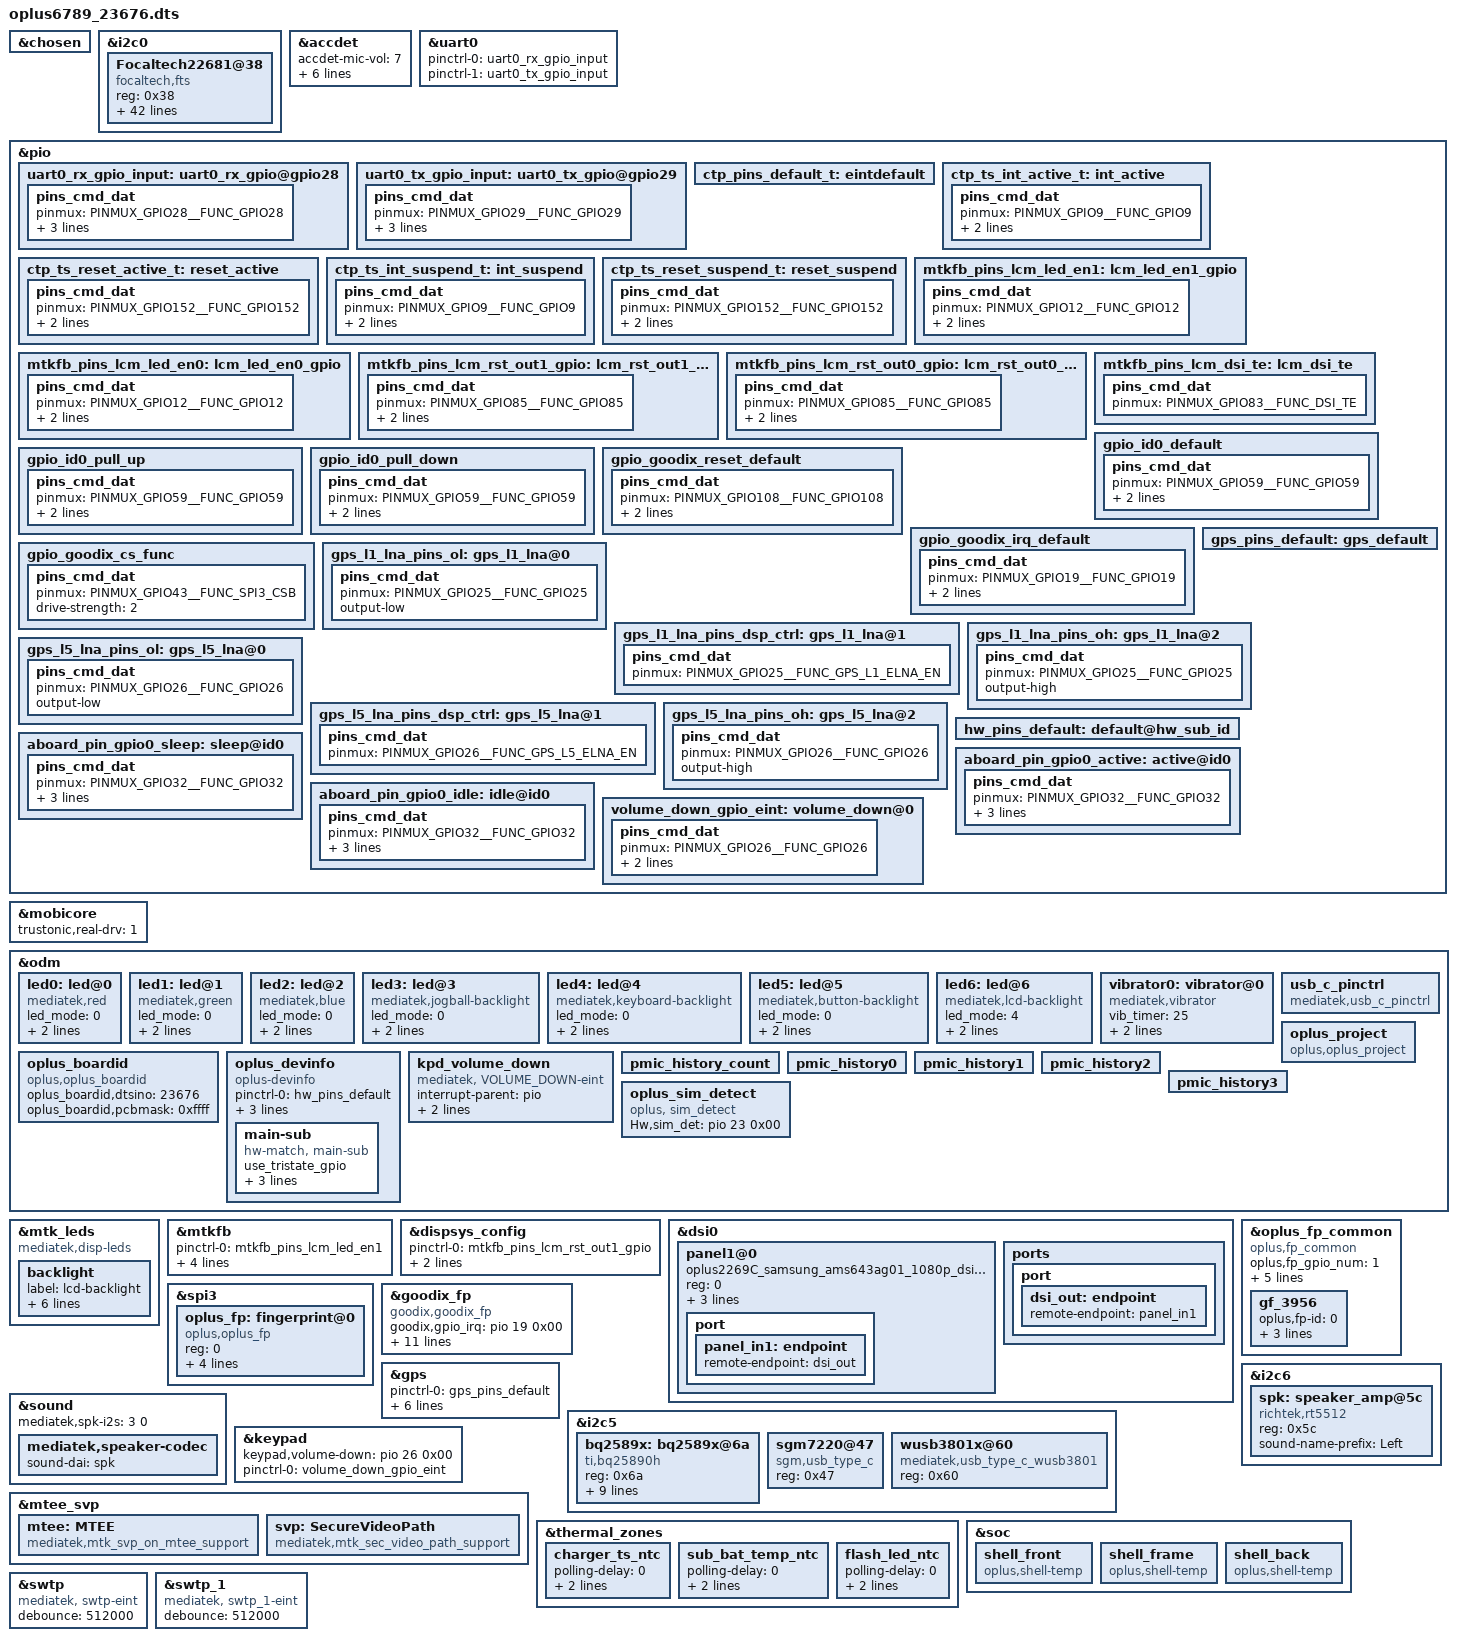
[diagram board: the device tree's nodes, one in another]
// SPDX-License-Identifier: (GPL-2.0 OR MIT)
/*
 * Copyright (C) 2021 MediaTek Inc.
 */
/dts-v1/;
/plugin/;
#include <dt-bindings/interrupt-controller/arm-gic.h>
#include <dt-bindings/interrupt-controller/irq.h>
#include <dt-bindings/pinctrl/mt6789-pinfunc.h>
#include "mediatek/cust_mt6789_camera_dokia.dtsi"
#include "mediatek/mt6789-sia8102.dtsi"
#include "mediatek/oplus6789_charger_23676.dtsi"
#include "mediatek/oplus_sensor_2269C.dtsi"
#include "mediatek/nfc/mt6789_doki_pn557.dtsi"

&chosen {

};

&i2c0 {
	status = "okay";
		Focaltech22681@38 {
		compatible = "focaltech,fts";
		reg = <0x38>;
		chip-name = "FT3518";

		/* Interrupt && Irq-gpio */
		interrupt-parent = <&pio>;
		interrupts = <9 0x2002>;

		/* Power Config */
		//vdd_2v8-supply  = <&mt_pmic_vtp_ldo_reg>;
		//vdd_2v8_volt = <3000000>;
		enable2v8_gpio = <&pio 153 0x1>;
		/* Other HW Resource */
		irq-gpio = <&pio 9 0x2002>;
		reset-gpio = <&pio 152 0x1>;
		//pinctrl-names = "default";
		//pinctrl-0 = <&ctp_ts_int_active &ctp_ts_reset_active>;
        panel_type = <8>;
		vid_len = <2>;
		tp_type = <8>;
		firmware_name = "0xAB54200";
		// type of tp_dev ,TP-SAMSUNG = 8;
		platform_support_project = <23676>;
		platform_support_project_dir = <0x2269C>;
		platform_support_project_commandline = "default_commandline";
		touchpanel,max-num-support = <10>;

		touchpanel,tx-rx-num = <16 34>;
		touchpanel,panel-coords = <8640 19200>;
		touchpanel,display-coords = <1080 2400>;
		touchpanel,touchmajor-limit = <0 216>;
		touchpanel,report-rate = <120 180>;
		touchpanel,smooth-level = <255 2 15 25 45 60>;
		touchpanel,smooth-level-charging = <255 15 20 25 45 60>;
		touchpanel,sensitive-level = <255 20 16 13 10 5>;
		touchpanel,single-optimized-time = <8>;

		//prevention,dead_area_width = <20 20>;
		//prevention,condition_area_width = <60 60 160 160>;
		//prevention,eli_area_width = <240 1000 1200 240>;

		/* SW Support Feature Control */
		black_gesture_support;
		black_gesture_indep_support;
		sportify_aod_gesture_support;
		fw_edge_limit_support;
		pressure_report_support;
		charger_pump_support;
		game_switch_support;
		smart_gesture_support;
		fw_update_app_support;
		fingerprint_underscreen_support;
		headset_pump_support;
		//irq_need_dev_resume_ok;
		health_monitor_support;
		high_resolution_support;
		high_resolution_support_x8;
		//esd_handle_support;
		lcd_tp_refresh_support;
		/*
		 *Virtual Key Config:
		 *1:touchpanel,button-type: <virtualkey_type  supportted_button-map>
		 *virtualkey_type:
		 *Type 1: using board_properties
		 *Type 2: using same IC (button zone&& touch zone are seprate)
		 *Type 3: using diffrent IC (button zone&& touch zone are seprate)
		 *Type 4: No need of virtual key process
		 *supportted_button-map:select|menu|home|back
		 *
		 *2:touchpanel,button-map
		 *type (X1,Y1)(X2,Y2)(X3,Y3)(Width_X,Hight_Y)--Only when button-type is 0
		 */
		touchpanel,button-type = <4>;
		touchpanel.button-TRx = <0 0>;
	};
};

/* accdet start */
&accdet {
    /* accdet micbias voltage: 0x07,2.7v;0x05,2.5v;0x02,1.9v */
    accdet-mic-vol = <7>;
    /* accdet pwm_width, pwm_thresh, fall_delay, rise_delay
     * debounce0, debounce1, debounce3, debounce4
     * eint pwm_width, eint pwm_thresh
     * eint deb(debounce0, debounce1, debounce2, debounce3), inv_debounce
     */
    headset-mode-setting = <0x500 0x500 1 0x1f0
                0x800 0x800 0x20 0x44
                0x4 0x1
                0x5 0x3 0x3 0x5 0xe>;
    accdet-plugout-debounce = <1>;
    /*0--MD_MAX--UP_MAX--DW_MAX*/
    headset-three-key-threshold = <0 82 170 400>;
    headset-three-key-threshold-CDD = <0 121 192 600>;
    /*0--MD_MAX--VOICE_MAX--UP_MAX--DW_MAX*/
    headset-four-key-threshold = <0 58 121 192 400>;
    status = "okay";
};
/* accdet end */

&uart0 {
	pinctrl-names = "uart0_rx_gpio",
		"uart0_tx_gpio";
	pinctrl-0 = <&uart0_rx_gpio_input>;
	pinctrl-1 = <&uart0_tx_gpio_input>;
	status = "okay";
};

&pio {
	uart0_rx_gpio_input:uart0_rx_gpio@gpio28 {
		pins_cmd_dat {
			pinmux = <PINMUX_GPIO28__FUNC_GPIO28>;
			input-enable;
			slew-rate = <0>;
			bias-pull-down;
		};
	};

	uart0_tx_gpio_input:uart0_tx_gpio@gpio29 {
		pins_cmd_dat {
			pinmux = <PINMUX_GPIO29__FUNC_GPIO29>;
			input-enable;
			slew-rate = <0>;
			bias-pull-down;
		};
	};
};
&pio {
	ctp_pins_default_t: eintdefault {
	};
	ctp_ts_int_active_t: int_active {
		pins_cmd_dat {
			pinmux = <PINMUX_GPIO9__FUNC_GPIO9>;
			slew-rate = <0>;
			bias-pull-down = <0>;
		};
	};
	ctp_ts_reset_active_t: reset_active {
		pins_cmd_dat {
			pinmux = <PINMUX_GPIO152__FUNC_GPIO152>;
			slew-rate = <1>;
			output-high;
		};
	};
	ctp_ts_int_suspend_t: int_suspend {
		pins_cmd_dat {
			pinmux = <PINMUX_GPIO9__FUNC_GPIO9>;
			slew-rate = <1>;
			output-low;
		};
	};
	ctp_ts_reset_suspend_t: reset_suspend {
		pins_cmd_dat {
			pinmux = <PINMUX_GPIO152__FUNC_GPIO152>;
			slew-rate = <0>;
			output-low;
		};
	};
};

/*start tee*/
&mobicore {
	trustonic,real-drv = <1>;
};
/*end tee*/

&odm {
	led0:led@0 {
		compatible = "mediatek,red";
		led_mode = <0>;
		data = <1>;
		pwm_config = <0 0 0 0 0>;
	};
	led1:led@1 {
		compatible = "mediatek,green";
		led_mode = <0>;
		data = <1>;
		pwm_config = <0 0 0 0 0>;
	};
	led2:led@2 {
		compatible = "mediatek,blue";
		led_mode = <0>;
		data = <1>;
		pwm_config = <0 0 0 0 0>;
	};
	led3:led@3 {
		compatible = "mediatek,jogball-backlight";
		led_mode = <0>;
		data = <1>;
		pwm_config = <0 0 0 0 0>;
	};
	led4:led@4 {
		compatible = "mediatek,keyboard-backlight";
		led_mode = <0>;
		data = <1>;
		pwm_config = <0 0 0 0 0>;
	};
	led5:led@5 {
		compatible = "mediatek,button-backlight";
		led_mode = <0>;
		data = <1>;
		pwm_config = <0 0 0 0 0>;
	};
	led6:led@6 {
		compatible = "mediatek,lcd-backlight";
		led_mode = <4>;
		data = <1>;
		pwm_config = <0 1 0 0 0>;
	};
	vibrator0:vibrator@0 {
		compatible = "mediatek,vibrator";
		vib_timer = <25>;
		vib_limit = <9>;
		vib_vol= <9>;
	};

	usb_c_pinctrl:usb_c_pinctrl {
		compatible = "mediatek,usb_c_pinctrl";
	};
};

&mtk_leds {
		compatible = "mediatek,disp-leds";
		backlight {
			label = "lcd-backlight";
			led_mode = <4>;
			max-brightness = <4095>;
			max-hw-brightness = <4095>;
			led-bits = <12>;
			trans-bits = <12>;
			default-state = "on";
	};
};

&pio {
	mtkfb_pins_lcm_led_en1: lcm_led_en1_gpio {
		pins_cmd_dat {
			pinmux = <PINMUX_GPIO12__FUNC_GPIO12>;
			slew-rate = <1>;
			output-high;
		};
	};

	mtkfb_pins_lcm_led_en0: lcm_led_en0_gpio {
		pins_cmd_dat {
			pinmux = <PINMUX_GPIO12__FUNC_GPIO12>;
			slew-rate = <1>;
			output-low;
		};
	};

	mtkfb_pins_lcm_rst_out1_gpio: lcm_rst_out1_gpio {
		pins_cmd_dat {
			pinmux = <PINMUX_GPIO85__FUNC_GPIO85>;
			slew-rate = <1>;
			output-high;
		};
	};

	mtkfb_pins_lcm_rst_out0_gpio: lcm_rst_out0_gpio {
		pins_cmd_dat {
			pinmux = <PINMUX_GPIO85__FUNC_GPIO85>;
			slew-rate = <1>;
			output-low;
		};
	};
	mtkfb_pins_lcm_dsi_te: lcm_dsi_te {
		pins_cmd_dat {
			pinmux = <PINMUX_GPIO83__FUNC_DSI_TE>;
		};
	};
};

&mtkfb {
	pinctrl-names = "lcm_led_en1_gpio", "lcm_led_en0_gpio",
		"lcm_rst_out1_gpio", "lcm_rst_out0_gpio",
		"mode_te_te";
	pinctrl-0 = <&mtkfb_pins_lcm_led_en1>;
	pinctrl-1 = <&mtkfb_pins_lcm_led_en0>;
	pinctrl-2 = <&mtkfb_pins_lcm_rst_out1_gpio>;
	pinctrl-3 = <&mtkfb_pins_lcm_rst_out0_gpio>;
	pinctrl-4 = <&mtkfb_pins_lcm_dsi_te>;
	status = "okay";
};

&dispsys_config {
	pinctrl-names =
		"lcm_rst_out1_gpio", "lcm_rst_out0_gpio",
		"mode_te_te";
	pinctrl-0 = <&mtkfb_pins_lcm_rst_out1_gpio>;
	pinctrl-1 = <&mtkfb_pins_lcm_rst_out0_gpio>;
	pinctrl-2 = <&mtkfb_pins_lcm_dsi_te>;
	status = "okay";
};

&dsi0 {
	status = "okay";
	#address-cells = <1>;
	#size-cells = <0>;
	panel1@0 {
		compatible = "oplus2269C_samsung_ams643ag01_1080p_dsi_cmd,lcm";
		reg = <0>;
		reset-gpios = <&pio 85 0>;
		bias-gpios = <&pio 110 0>;
		gate-ic = <4831>;
		pinctrl-names = "default";
		port {
			panel_in1: endpoint {
				remote-endpoint = <&dsi_out>;
			};
		};
	};
	ports {
		port {
			dsi_out: endpoint {
				remote-endpoint = <&panel_in1>;
			};
		};
	};
};

//#ifdef OPLUS_FEATURE_FINGERPRINT
&oplus_fp_common {
	compatible = "oplus,fp_common";
	oplus,fp_gpio_num = <1>;
	oplus,fp_gpio = <59>;
	oplus,fp_gpio_0 = <&pio 59 0x0>;
	pinctrl-names = "gpio_id0_default", "gpio_id0_pull_up", "gpio_id0_pull_down"; /* Compatible with multiple fingerprints */
	pinctrl-0 = <&gpio_id0_default>;
	pinctrl-1 = <&gpio_id0_pull_up>;
	pinctrl-2 = <&gpio_id0_pull_down>;
	gf_3956 {
		oplus,fp-id = <0>; /* fp id mapping table */
		vendor-chip = <27>; /* please refer to the struct fp_vendor_t in oplus_fp_commmon.h */
		eng-menu = "-1,-1"; /* represents SNR, inclination test item in engineer menu, and 0/1 means off/on */
		chip-name = "G_3956";  /* /proc/fp_id, will be displayed in engineer menu  */
	};
};

&pio{
	gpio_id0_default: gpio_id0_default {
		pins_cmd_dat {
			pinmux = <PINMUX_GPIO59__FUNC_GPIO59>;
			slew-rate = <0>;
			bias-pull-up = <00>;
		};
	};
	gpio_id0_pull_up: gpio_id0_pull_up {
		pins_cmd_dat {
			pinmux = <PINMUX_GPIO59__FUNC_GPIO59>;
			slew-rate = <0>;
			bias-pull-up = <00>;
		};
	};
	gpio_id0_pull_down: gpio_id0_pull_down {
		pins_cmd_dat {
			pinmux = <PINMUX_GPIO59__FUNC_GPIO59>;
			slew-rate = <0>;
			bias-pull-down = <00>;
		};
	};
};

&spi3 {
#address-cells = <1>;
#size-cells = <0>;
status = "okay";
oplus_fp: fingerprint@0 {
		compatible = "oplus,oplus_fp";
		reg = <0>;
		spi-max-frequency = <8000000>;
		spi-id = <3>;
		spi-irq = <22>;
		spi-reg = <11013000>;
		status = "okay";
		/*power_source_1 {
			power-mode = <0>;
			power-name = "dvdd";
			power-config = "dvdd-config";
			delay-time = <0>;
		};*/
	};
};
&goodix_fp {
	compatible = "goodix,goodix_fp";
	goodix,gpio_irq = <&pio 19 0x00>;
	goodix,gpio_reset = <&pio 108 0x00>;
	goodix,gpio_cs = <&pio 43 0x00>;
	//gf,cs_gpio_disable = <1>;
	gf,enable-external-pmic;
	gf,ext-pmic-ldo-num = <4>;
	gf,ext-pmic-ldo-mv-max = <3000>;
	gf,ext-pmic-ldo-mv-min = <0>;
	interrupt-parent = <&pio>;
	interrupts = <19 IRQ_TYPE_EDGE_RISING 19 0>;
	pinctrl-names = "default", "gf_cs_func";
	pinctrl-0 = <&gpio_goodix_irq_default>, <&gpio_goodix_reset_default>;
	pinctrl-1 = <&gpio_goodix_cs_func>;
	status = "okay";
};
&pio {
	gpio_goodix_reset_default: gpio_goodix_reset_default {
		pins_cmd_dat {
			pinmux = <PINMUX_GPIO108__FUNC_GPIO108>;
			slew-rate = <1>;
			output-low;
		};
	};
	gpio_goodix_irq_default: gpio_goodix_irq_default {
		pins_cmd_dat {
			pinmux = <PINMUX_GPIO19__FUNC_GPIO19>;
			slew-rate = <0>;
			bias-pull-down;
		};
	};
	gpio_goodix_cs_func: gpio_goodix_cs_func {
		pins_cmd_dat {
			pinmux = <PINMUX_GPIO43__FUNC_SPI3_CSB>;
			drive-strength = <2>;
		};
	};
};
//#endif /*OPLUS_FEATURE_FINGERPRINT*/

/* GPS GPIO standardization start */
&pio {
	gps_pins_default: gps_default {
	};
	gps_l1_lna_pins_ol: gps_l1_lna@0 {
		pins_cmd_dat {
			pinmux = <PINMUX_GPIO25__FUNC_GPIO25>;
			output-low;
		};
	};
	gps_l1_lna_pins_dsp_ctrl: gps_l1_lna@1 {
		pins_cmd_dat {
			pinmux = <PINMUX_GPIO25__FUNC_GPS_L1_ELNA_EN>;
		};
	};
	gps_l1_lna_pins_oh: gps_l1_lna@2 {
		pins_cmd_dat {
			pinmux = <PINMUX_GPIO25__FUNC_GPIO25>;
			output-high;
		};
	};
	gps_l5_lna_pins_ol: gps_l5_lna@0 {
		pins_cmd_dat {
			pinmux = <PINMUX_GPIO26__FUNC_GPIO26>;
			output-low;
		};
	};
	gps_l5_lna_pins_dsp_ctrl: gps_l5_lna@1 {
		pins_cmd_dat {
			pinmux = <PINMUX_GPIO26__FUNC_GPS_L5_ELNA_EN>;
		};
	};
	gps_l5_lna_pins_oh: gps_l5_lna@2 {
		pins_cmd_dat {
			pinmux = <PINMUX_GPIO26__FUNC_GPIO26>;
			output-high;
		};
	};
};
&gps {
	pinctrl-names = "default",
		"gps_l1_lna_disable",
		"gps_l1_lna_dsp_ctrl",
		"gps_l1_lna_enable",
		"gps_l5_lna_disable",
		"gps_l5_lna_dsp_ctrl",
		"gps_l5_lna_enable";
	pinctrl-0 = <&gps_pins_default>;
	pinctrl-1 = <&gps_l1_lna_pins_ol>;
	pinctrl-2 = <&gps_l1_lna_pins_dsp_ctrl>;
	pinctrl-3 = <&gps_l1_lna_pins_oh>;
	pinctrl-4 = <&gps_l5_lna_pins_ol>;
	pinctrl-5 = <&gps_l5_lna_pins_dsp_ctrl>;
	pinctrl-6 = <&gps_l5_lna_pins_oh>;
	status = "okay";
};
/* GPS GPIO standardization end */

#include "mediatek/cust_mt6789_touch_1080x2400.dtsi"
#include "mediatek/cust_mt6789_camera_doki_v4l2.dtsi"
&i2c5 {
	bq2589x:bq2589x@6a {
		compatible = "ti,bq25890h";
		reg = <0x6a>;
		interrupt-parent = <&pio>;
		interrupts = <4 IRQ_TYPE_EDGE_FALLING 4 0>;
		ti,bq2589x,usb-vlim =<4400>;
		ti,bq2589x,precharge-current = <256>;
		ti,bq2589x,termination-current = <250>;
		ti,bq2589x,boost-voltage = <5062>;
		ti,bq2589x,charge-detect-enable;
			/*
			* Charger name
			* Main charger: primary_chg
			* Slave charger: secondary_chg
			*/
		charger_name = "primary_chg";
		eint_name = "bq2589x";
		status = "okay";
	};
	sgm7220@47 {
		compatible = "sgm,usb_type_c";
		reg = <0x47>;
		status = "okay";
	};
	wusb3801x@60 {
		compatible = "mediatek,usb_type_c_wusb3801";
		reg = <0x60>;
		status = "okay";
	};
};

&i2c6 {
	spk: speaker_amp@5c {
		compatible = "richtek,rt5512";
		#sound-dai-cells = <0>;
		reg = <0x5c>;
		status = "okay";
		sound-name-prefix = "Left";
	};
};

&sound {
	mediatek,spk-i2s = <3 0>;
	mediatek,speaker-codec {
		sound-dai = <&spk>;
	};
};

&pio {
	hw_pins_default:default@hw_sub_id {
	};
	aboard_pin_gpio0_sleep:sleep@id0 {
		pins_cmd_dat {
			pinmux = <PINMUX_GPIO32__FUNC_GPIO32>;
			slew-rate = <0>;
			bias-pull-down;
			input-enable;
		};
	};

	aboard_pin_gpio0_active:active@id0 {
		pins_cmd_dat {
			pinmux = <PINMUX_GPIO32__FUNC_GPIO32>;
			slew-rate = <0>;
			bias-pull-up;
			input-enable;
		};
	};

	aboard_pin_gpio0_idle:idle@id0 {
		pins_cmd_dat {
			pinmux = <PINMUX_GPIO32__FUNC_GPIO32>;
			slew-rate = <0>;
			bias-disable;
			input-enable;
		};
	};
};
/*#endif OPLUS_FEATURE_TP_BASIC*/

&odm {
/*OPLUS_BUG_STABILITY oplus project start */
	oplus_project:oplus_project {
		compatible = "oplus,oplus_project";
	};
/*endif*/

oplus_boardid:oplus_boardid {
		compatible = "oplus,oplus_boardid";
		oplus_boardid,dtsino="23676";//only one u32
		oplus_boardid,pcbmask="0xffff";//all mask 0xffff
	};

	oplus_devinfo:oplus_devinfo {
		compatible = "oplus-devinfo";
		pinctrl-names = "default", "aboard_gpio0_sleep", "aboard_gpio0_active", "aboard_gpio0_idle";
		pinctrl-0 = <&hw_pins_default>;
		pinctrl-1 = <&aboard_pin_gpio0_sleep>;
		pinctrl-2 = <&aboard_pin_gpio0_active>;
		pinctrl-3 = <&aboard_pin_gpio0_idle>;
		main-sub {
			use_tristate_gpio;
			compatible = "hw-match, main-sub";
			aboard-gpio0 = <&pio 32 0x00>;
			aboard-patterns = <1>;	/*0[high-resistance] 1[pull-down] 2[pull-up]*/
			/*main board*/
			match-projects = <23676>;
		};
	};
	/*#endif OPLUS_FEATURE_TP_BASIC*/

	kpd_volume_down:kpd_volume_down {
                compatible = "mediatek, VOLUME_DOWN-eint";
                interrupt-parent = <&pio>;
                interrupts = <26 IRQ_TYPE_EDGE_FALLING 26 0>;
                debounce = <32000>;
                status = "okay";
        };

	pmic_history_count:pmic_history_count {
	};
	pmic_history0:pmic_history0 {
	};
	pmic_history1:pmic_history1 {
	};
	pmic_history2:pmic_history2 {
	};
	pmic_history3:pmic_history3 {
	};

};

&odm {
    oplus_sim_detect {
        compatible = "oplus, sim_detect";
        Hw,sim_det = <&pio 23 0x00>;
    };
};

&keypad {
	keypad,volume-down = <&pio 26 0x00>;
	pinctrl-names = "volume_down_as_int";
	pinctrl-0 = <&volume_down_gpio_eint>;
	status = "okay";
};
&pio {
	volume_down_gpio_eint:volume_down@0{
		pins_cmd_dat {
			pinmux = <PINMUX_GPIO26__FUNC_GPIO26>;
			slew-rate = <0>;  /*direction 0:in, 1:out*/
			input-enable;
		};
	};
};
//ifdef OPLUS_FEATURE_SECURITY_COMMON
&mtee_svp {
     mtee: MTEE {
         compatible = "mediatek,mtk_svp_on_mtee_support";
    };
    svp: SecureVideoPath {
        compatible = "mediatek,mtk_sec_video_path_support";
    };
};
//endif /* OPLUS_FEATURE_SECURITY_COMMON */
/*add charger_ts_ntc sub_bat_temp_ntc flash_led_ntc for thermal  begin(2)*/
&thermal_zones {
	charger_ts_ntc: charger_ts_ntc {
			polling-delay = <0>; /* milliseconds */
			polling-delay-passive = <0>; /* milliseconds */
			thermal-sensors = <&tboard_thermistor5>;
		};
	sub_bat_temp_ntc: sub_bat_temp_ntc {
			polling-delay = <0>; /* milliseconds */
			polling-delay-passive = <0>; /* milliseconds */
			thermal-sensors = <&tboard_thermistor6>;
		};
	flash_led_ntc: flash_led_ntc {
			polling-delay = <0>; /* milliseconds */
			polling-delay-passive = <0>; /* milliseconds */
			thermal-sensors = <&tboard_thermistor7>;
		};
};
/*add charger_ts_ntc sub_bat_temp_ntc flash_led_ntc for thermal end(2)*/
/*add for shell-temp begin*/
&soc {
	//#ifdef OPLUS_FEATURE_THERMAL_HORAE
	shell_front {
			compatible = "oplus,shell-temp";
		};
	shell_frame {
			compatible = "oplus,shell-temp";
		};
	shell_back {
			compatible = "oplus,shell-temp";
		};
	//#endif
};
/*add for shell-temp end*/
//#ifdef OPLUS_FEATURE_SWTP
&swtp {
	compatible = "mediatek, swtp-eint";
	debounce = <512000>;
};
&swtp_1 {
	compatible = "mediatek, swtp_1-eint";
	debounce = <512000>;
};
//#endif  /* OPLUS_FEATURE_SWTP */
#include <oplus6789_23676/cust.dtsi>
/*End of this file, DO NOT ADD ANYTHING HERE*/
